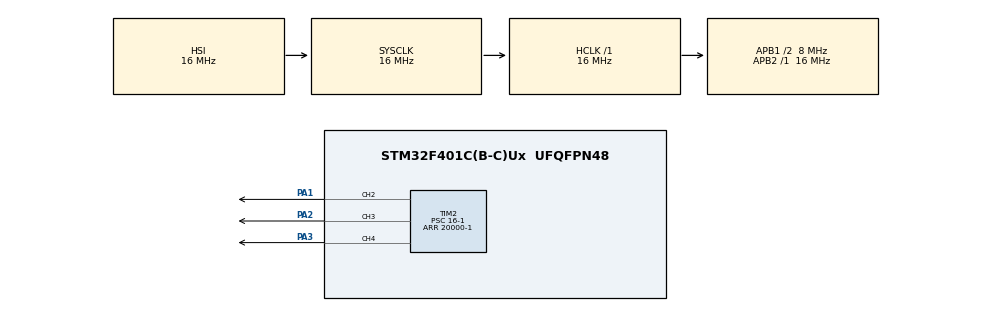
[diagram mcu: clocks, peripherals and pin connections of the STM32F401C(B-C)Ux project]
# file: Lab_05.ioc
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Mcu.Family=STM32F4
Mcu.Name=STM32F401C(B-C)Ux
Mcu.Package=UFQFPN48
NVIC.PriorityGroup=NVIC_PRIORITYGROUP_4
NVIC.TIM3_IRQn=true\:0\:0\:false\:true\:true\:1\:true\:true\:true
PA1.Signal=S_TIM2_CH2
PA2.Signal=S_TIM2_CH3
PA3.Signal=S_TIM2_CH4
ProjectManager.HeapSize=0x200
ProjectManager.StackSize=0x400
ProjectManager.TargetToolchain=STM32CubeIDE
RCC.AHBFreq_Value=16000000
RCC.APB1CLKDivider=RCC_HCLK_DIV2
RCC.APB1Freq_Value=8000000
RCC.APB1TimFreq_Value=16000000
RCC.APB2Freq_Value=16000000
RCC.APB2TimFreq_Value=16000000
RCC.CortexFreq_Value=16000000
RCC.HCLKFreq_Value=16000000
RCC.HSE_VALUE=25000000
RCC.HSI_VALUE=16000000
RCC.LSE_VALUE=32768
RCC.SYSCLKFreq_VALUE=16000000
RCC.VCOOutputFreq_Value=192000000
SH.S_TIM2_CH2.0=TIM2_CH2,PWM Generation2 CH2
SH.S_TIM2_CH3.0=TIM2_CH3,PWM Generation3 CH3
SH.S_TIM2_CH4.0=TIM2_CH4,PWM Generation4 CH4
TIM2.Channel-PWM\ Generation2\ CH2=TIM_CHANNEL_2
TIM2.Channel-PWM\ Generation3\ CH3=TIM_CHANNEL_3
TIM2.Channel-PWM\ Generation4\ CH4=TIM_CHANNEL_4
TIM2.Period=20000-1
TIM2.Prescaler=16-1
TIM2.Pulse-PWM\ Generation2\ CH2=1250
TIM2.Pulse-PWM\ Generation3\ CH3=1500
TIM2.Pulse-PWM\ Generation4\ CH4=17500
TIM3.AutoReloadPreload=TIM_AUTORELOAD_PRELOAD_DISABLE
TIM3.Period=10-1
TIM3.Prescaler=16000-1
VP_TIM2_VS_ClockSourceINT.Mode=Internal
VP_TIM3_VS_ClockSourceINT.Mode=Internal
board=custom

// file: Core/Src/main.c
/* USER CODE BEGIN Header */
/**
  ******************************************************************************
  * @file           : main.c
  * @brief          : Main program body
  ******************************************************************************
  * @attention
  *
  * Copyright (c) 2022 STMicroelectronics.
  * All rights reserved.
  *
  * This software is licensed under terms that can be found in the LICENSE file
  * in the root directory of this software component.
  * If no LICENSE file comes with this software, it is provided AS-IS.
  *
  ******************************************************************************
  */
/* USER CODE END Header */
#include "main.h"
#include "tim.h"
#include "gpio.h"

void SystemClock_Config(void);
static void MX_NVIC_Init(void);

int main(void)
{

  /* MCU Configuration--------------------------------------------------------*/

  /* Reset of all peripherals, Initializes the Flash interface and the Systick. */
  HAL_Init();

  /* Configure the system clock */
  SystemClock_Config();

  /* Initialize all configured peripherals */
  MX_GPIO_Init();
  MX_TIM2_Init();
  MX_TIM3_Init();

  /* Initialize interrupts */
  MX_NVIC_Init();
  /* USER CODE BEGIN 2 */
  HAL_TIM_Base_Start_IT(&htim3);
  HAL_TIM_PWM_Start(&htim2, TIM_CHANNEL_2);
  HAL_TIM_PWM_Start(&htim2, TIM_CHANNEL_3);
  HAL_TIM_PWM_Start(&htim2, TIM_CHANNEL_4);

  /* USER CODE END 2 */

  /* Infinite loop */
  while (1)
  {

  }
}

void SystemClock_Config(void)
{
  RCC_OscInitTypeDef RCC_OscInitStruct = {0};
  RCC_ClkInitTypeDef RCC_ClkInitStruct = {0};

  /** Configure the main internal regulator output voltage
  */
  __HAL_RCC_PWR_CLK_ENABLE();
  __HAL_PWR_VOLTAGESCALING_CONFIG(PWR_REGULATOR_VOLTAGE_SCALE2);

  /** Initializes the RCC Oscillators according to the specified parameters
  * in the RCC_OscInitTypeDef structure.
  */
  RCC_OscInitStruct.OscillatorType = RCC_OSCILLATORTYPE_HSI;
  RCC_OscInitStruct.HSIState = RCC_HSI_ON;
  RCC_OscInitStruct.HSICalibrationValue = RCC_HSICALIBRATION_DEFAULT;
  RCC_OscInitStruct.PLL.PLLState = RCC_PLL_NONE;
  if (HAL_RCC_OscConfig(&RCC_OscInitStruct) != HAL_OK)
  {
    Error_Handler();
  }

  /** Initializes the CPU, AHB and APB buses clocks
  */
  RCC_ClkInitStruct.ClockType = RCC_CLOCKTYPE_HCLK|RCC_CLOCKTYPE_SYSCLK
                              |RCC_CLOCKTYPE_PCLK1|RCC_CLOCKTYPE_PCLK2;
  RCC_ClkInitStruct.SYSCLKSource = RCC_SYSCLKSOURCE_HSI;
  RCC_ClkInitStruct.AHBCLKDivider = RCC_SYSCLK_DIV1;
  RCC_ClkInitStruct.APB1CLKDivider = RCC_HCLK_DIV2;
  RCC_ClkInitStruct.APB2CLKDivider = RCC_HCLK_DIV1;

  if (HAL_RCC_ClockConfig(&RCC_ClkInitStruct, FLASH_LATENCY_0) != HAL_OK)
  {
    Error_Handler();
  }
}

/**
  * @brief NVIC Configuration.
  * @retval None
  */
static void MX_NVIC_Init(void)
{
  /* TIM3_IRQn interrupt configuration */
  HAL_NVIC_SetPriority(TIM3_IRQn, 0, 0);
  HAL_NVIC_EnableIRQ(TIM3_IRQn);
}

/* USER CODE BEGIN 4 */
int myPulsePWM1 = 1500;
int flag = 0;
int flag1 = 0;
int myPulsePWM2=1250;
void HAL_TIM_PeriodElapsedCallback(TIM_HandleTypeDef *htim)
{

	if(htim->Instance == TIM3)
	{
		if(myPulsePWM1<2000 && flag == 0)
		{
			myPulsePWM1 +=10;
			if(myPulsePWM1 == 2000)
			{
				flag = 1;
				__HAL_TIM_SetCompare(&htim2, TIM_CHANNEL_3, myPulsePWM1);

			}

		}

		if(myPulsePWM1 > 1000 && flag == 1)
		{
			myPulsePWM1 -=10;
			if(myPulsePWM1 == 1000)
			{
				flag = 0;
				__HAL_TIM_SetCompare(&htim2, TIM_CHANNEL_3, myPulsePWM1);

			}
		}

	 }
	if(htim->Instance == TIM3)
	{
		if(myPulsePWM2 < 1750 && flag1 == 0)
		{
			myPulsePWM2 +=10;
			if(myPulsePWM2 == 1750)
			{
				flag1 = 1;
				__HAL_TIM_SetCompare(&htim2, TIM_CHANNEL_4, myPulsePWM2);

			}
		}

	if(myPulsePWM2 > 1250 && flag1 == 1)
	{
		myPulsePWM2 -=10;
		if(myPulsePWM2 == 1250)
		{
			flag1 = 0;
			__HAL_TIM_SetCompare(&htim2, TIM_CHANNEL_4, myPulsePWM2);

		}
		}
	}

}
/* USER CODE END 4 */

void Error_Handler(void)
{
  __disable_irq();
  while (1)
  {
  }
}
